# SAMA7G54D4G device description
Architecture: CORTEX-A7; Family: SAMA; Series: SAMA7G
Registers are 32-bit, read-write, reset 0x0 unless marked. A register's access mark holds for its fields unless they carry their own. Offsets are from the block's base; [hi:lo] are bit positions; {n}, {i} and the like mark numbered series.

## ICM — Integrity Check Monitor
Instances: ICM 0xE081C000
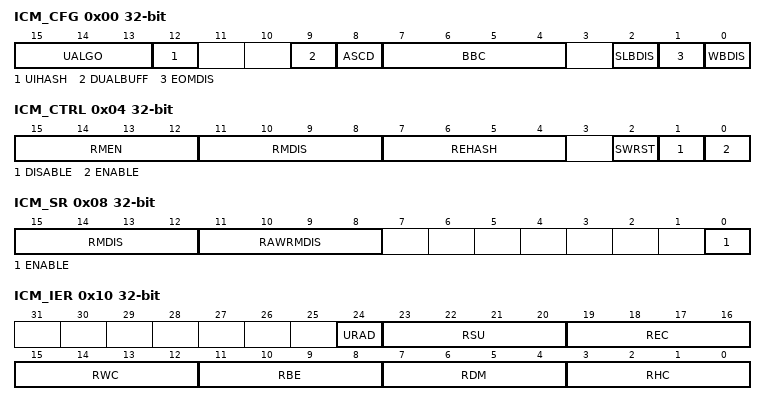
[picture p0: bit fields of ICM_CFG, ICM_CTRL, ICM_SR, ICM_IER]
0x00 ICM_CFG — Configuration Register
  [15:13] UALGO — User SHA Algorithm
    0=SHA1 (SHA1 algorithm processed); 1=SHA256 (SHA256 algorithm processed); 4=SHA224 (SHA224 algorithm processed)
  [12] UIHASH — User Initial Hash Value
    0=The secure hash standard provides the initial hash value; 1=The initial hash value is programmable. Field UALGO provides the SHA algorithm. The ALGO field of the ICM_RCFG structure member has no effect.
  [9] DUALBUFF — Dual Input Buffer
    0=Dual Input Buffer mode is disabled; 1=Dual Input Buffer mode is enabled (better performances, higher bandwidth required on system bus)
  [8] ASCD — Automatic Switch To Compare Digest
    0=Automatic monitoring mode is disabled; 1=The ICM passes through the Main List once to calculate the message digest of the monitored area. When WRAP = 1 in ICM_RCFG, the ICM begins monitoring.
  [7:4] BBC — Bus Burden Control
  [2] SLBDIS — Secondary List Branching Disable
    0=Branching to the Secondary List is permitted; 1=Branching to the Secondary List is forbidden. The NEXT field of the ICM_RNEXT structure member has no effect and is always considered as zero.
  [1] EOMDIS — End of Monitoring Disable
    0=End of Monitoring is permitted; 1=End of Monitoring is forbidden. The EOM bit of the ICM_RCFG structure member has no effect.
  [0] WBDIS — Write-Back Disable
    0=Write-back operations are permitted; 1=Write-back operations are forbidden. Context register CDWBN bit is internally set to one and cannot be modified by a linked list element. ICM_RCFG.CDWBN has no effect.
0x04 ICM_CTRL wo reset not defined — Control Register
  [15:12] RMEN — Region Monitoring Enable
    0=No effect; 1=When bit RMEN[i] is set to one, the monitoring of region with identifier i is activated
  [11:8] RMDIS — Region Monitoring Disable
    0=No effect; 1=When bit RMDIS[i] is set to one, the monitoring of region with identifier i is disabled
  [7:4] REHASH — Recompute Internal Hash
    0=No effect; 1=When REHASH[i] is set to one, Region i digest is re-computed. This bit is only available when region monitoring is disabled.
  [2] SWRST — Software Reset
    0=No effect; 1=Resets the ICM
  [1] DISABLE — ICM Disable Register
    0=No effect; 1=The ICM is disabled. If a region is active, this region is terminated.
  [0] ENABLE — ICM Enable
    0=No effect; 1=When set to one, the ICM is activated
0x08 ICM_SR ro — Status Register
  [15:12] RMDIS — Region Monitoring Disabled Status
    0=Region i is being monitored (occurs after integrity check value has been calculated and written to Hash area); 1=Region i monitoring is not being monitored
  [11:8] RAWRMDIS — Region Monitoring Disabled Raw Status
    0=Region i monitoring has been activated by writing a 1 in RMEN[i] of ICM_CTRL; 1=Region i monitoring has been deactivated by writing a 1 in RMDIS[i] of ICM_CTRL
  [0] ENABLE — ICM Enable Register
    0=ICM is disabled; 1=ICM is activated
0x10 ICM_IER wo reset not defined (atomic set of ICM_IMR) — Interrupt Enable Register
  [24] URAD — Undefined Register Access Detection Interrupt Enable
    0=No effect; 1=The Undefined Register Access interrupt is enabled
  [23:20] RSU — Region Status Updated Interrupt Disable
    0=No effect; 1=When RSU[i] is set to one, the region i Status Updated interrupt is enabled
  [19:16] REC — Region End bit Condition Detected Interrupt Enable
    0=No effect; 1=When REC[i] is set to one, the region i End bit Condition interrupt is enabled
  [15:12] RWC — Region Wrap Condition detected Interrupt Enable
    0=No effect; 1=When RWC[i] is set to one, the Region i Wrap Condition interrupt is enabled
  [11:8] RBE — Region Bus Error Interrupt Enable
    0=No effect; 1=When RBE[i] is set to one, the Region i Bus Error interrupt is enabled
  [7:4] RDM — Region Digest Mismatch Interrupt Enable
    0=No effect; 1=When RDM[i] is set to one, the Region i Digest Mismatch interrupt is enabled
  [3:0] RHC — Region Hash Completed Interrupt Enable
    0=No effect; 1=When RHC[i] is set to one, the Region i Hash Completed interrupt is enabled
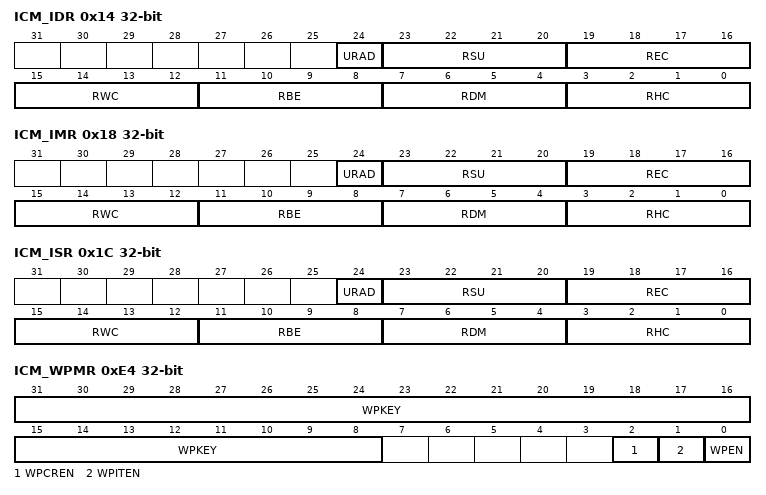
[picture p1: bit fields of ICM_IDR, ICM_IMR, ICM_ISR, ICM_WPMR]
0x14 ICM_IDR wo reset not defined (atomic clear of ICM_IMR) — Interrupt Disable Register
  [24] URAD — Undefined Register Access Detection Interrupt Disable
    0=No effect; 1=Undefined Register Access Detection interrupt is disabled
  [23:20] RSU — Region Status Updated Interrupt Disable
    0=No effect; 1=When RSU[i] is set to one, the region i Status Updated interrupt is disabled
  [19:16] REC — Region End bit Condition detected Interrupt Disable
    0=No effect; 1=When REC[i] is set to one, the region i End bit Condition interrupt is disabled
  [15:12] RWC — Region Wrap Condition Detected Interrupt Disable
    0=No effect; 1=When RWC[i] is set to one, the Region i Wrap Condition interrupt is disabled
  [11:8] RBE — Region Bus Error Interrupt Disable
    0=No effect; 1=When RBE[i] is set to one, the Region i Bus Error interrupt is disabled
  [7:4] RDM — Region Digest Mismatch Interrupt Disable
    0=No effect; 1=When RDM[i] is set to one, the Region i Digest Mismatch interrupt is disabled
  [3:0] RHC — Region Hash Completed Interrupt Disable
    0=No effect; 1=When RHC[i] is set to one, the Region i Hash Completed interrupt is disabled
0x18 ICM_IMR ro — Interrupt Mask Register
  [24] URAD — Undefined Register Access Detection Interrupt Mask
    0=Interrupt is disabled; 1=Interrupt is enabled
  [23:20] RSU — Region Status Updated Interrupt Mask
    0=When RSU[i] is set to zero, the interrupt is disabled for region i; 1=When RSU[i] is set to one, the interrupt is enabled for region i
  [19:16] REC — Region End bit Condition Detected Interrupt Mask
    0=When REC[i] is set to zero, the interrupt is disabled for region i; 1=When REC[i] is set to one, the interrupt is enabled for region i
  [15:12] RWC — Region Wrap Condition Detected Interrupt Mask
    0=When RWC[i] is set to zero, the interrupt is disabled for region i; 1=When RWC[i] is set to one, the interrupt is enabled for region i
  [11:8] RBE — Region Bus Error Interrupt Mask
    0=When RBE[i] is set to zero, the interrupt is disabled for region i; 1=When RBE[i] is set to one, the interrupt is enabled for region i
  [7:4] RDM — Region Digest Mismatch Interrupt Mask
    0=When RDM[i] is set to zero, the interrupt is disabled for region i; 1=When RDM[i] is set to one, the interrupt is enabled for region i
  [3:0] RHC — Region Hash Completed Interrupt Mask
    0=When RHC[i] is set to zero, the interrupt is disabled for region i; 1=When RHC[i] is set to one, the interrupt is enabled for region i
0x1C ICM_ISR ro — Interrupt Status Register
  [24] URAD — Undefined Register Access Detection Status
    0=No undefined register access has been detected since the last SWRST; 1=At least one undefined register access has been detected since the last SWRST
  [23:20] RSU — Region Status Updated Detected
  [19:16] REC — Region End Bit Condition Detected
  [15:12] RWC — Region Wrap Condition Detected
  [11:8] RBE — Region Bus Error
  [7:4] RDM — Region Digest Mismatch
  [3:0] RHC — Region Hash Completed
0x20 ICM_UASR ro — Undefined Access Status Register
  [2:0] URAT — Undefined Register Access Trace
    0=UNSPEC_STRUCT_MEMBER (Unspecified structure member set to one detected when the descriptor is loaded.); 1=ICM_CFG_MODIFIED (ICM_CFG modified during active monitoring.); 2=ICM_DSCR_MODIFIED (ICM_DSCR modified during active monitoring.); 3=ICM_HASH_MODIFIED (ICM_HASH modified during active monitoring); 4=READ_ACCESS (Write-only register read access)
0x30 ICM_DSCR — Region Descriptor Area Start Address Register
  [31:6] DASA — Descriptor Area Start Address
0x34 ICM_HASH — Region Hash Area Start Address Register
  [31:7] HASA — Hash Area Start Address
{0x38+4i} ICM_UIHVAL[{i}] (i=0..7) wo reset not defined — User Initial Hash Value x Register
  [31:0] VAL — Initial Hash Value
0xE4 ICM_WPMR — Write Protection Mode Register
  [31:8] WPKEY — Write Protection Key
    0x49434D=PASSWD (Writing any other value in this field aborts the write operation of the WPEN, WPITEN and WPCREN bits. Always reads as 0)
  [2] WPCREN — Write Protection Control Enable
    0=Disables the write protection on control register if WPKEY corresponds to 0x49434D ("ICM" in ASCII); 1=Enables the write protection on control register if WPKEY corresponds to 0x49434D ("ICM" in ASCII)
  [1] WPITEN — Write Protection Interrupt Enable
    0=Disables the write protection on interrupt registers if WPKEY corresponds to 0x49434D ("ICM" in ASCII); 1=Enables the write protection on interrupt registers if WPKEY corresponds to 0x49434D ("ICM" in ASCII)
  [0] WPEN — Write Protection Enable
    0=Disables the write protection if WPKEY corresponds to 0x49434D ("ICM" in ASCII); 1=Enables the write protection if WPKEY corresponds to 0x49434D ("ICM" in ASCII)
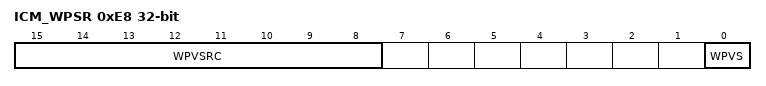
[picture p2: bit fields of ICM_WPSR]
0xE8 ICM_WPSR ro — Write Protection Status Register
  [15:8] WPVSRC — Write Protection Violation Source
  [0] WPVS — Write Protection Violation Status (Cleared on read)
    0=No write protect violation has occurred since the last read of ICM_WPSR; 1=A write protect violation has occurred since the last read of ICM_WPSR. If this violation is an unauthorized attempt to write a protected register, the associated violation is reported into field WPVSRC.
